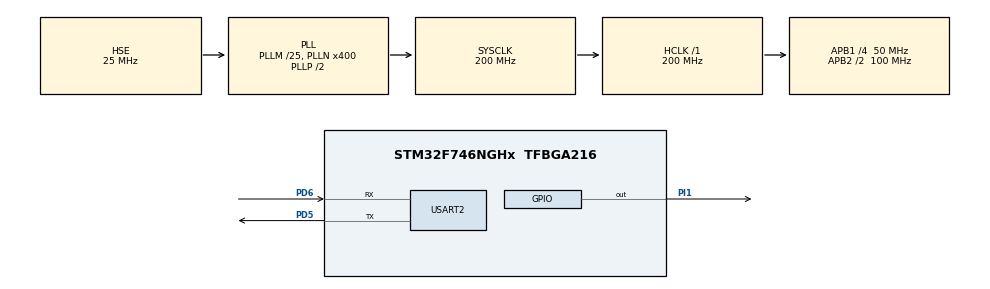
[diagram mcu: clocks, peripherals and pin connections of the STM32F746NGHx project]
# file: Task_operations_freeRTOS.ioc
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FREERTOS.INCLUDE_vTaskDelayUntil=1
FREERTOS.Tasks01=defaultTask,0,128,StartDefaultTask,Default,NULL,Dynamic,NULL,NULL;Task2,0,128,task2_init,Default,NULL,Dynamic,NULL,NULL
Mcu.Family=STM32F7
Mcu.Name=STM32F746NGHx
Mcu.Package=TFBGA216
NVIC.PriorityGroup=NVIC_PRIORITYGROUP_4
NVIC.TIM1_UP_TIM10_IRQn=true\:15\:0\:false\:false\:true\:false\:false\:true
NVIC.TimeBase=TIM1_UP_TIM10_IRQn
NVIC.TimeBaseIP=TIM1
PA13.Mode=Serial_Wire
PA13.Signal=SYS_JTMS-SWDIO
PA14.Mode=Serial_Wire
PA14.Signal=SYS_JTCK-SWCLK
PD5.Mode=Asynchronous
PD5.Signal=USART2_TX
PD6.Mode=Asynchronous
PD6.Signal=USART2_RX
PH0/OSC_IN.Mode=HSE-External-Oscillator
PH0/OSC_IN.Signal=RCC_OSC_IN
PH1/OSC_OUT.Mode=HSE-External-Oscillator
PH1/OSC_OUT.Signal=RCC_OSC_OUT
PI1.Signal=GPIO_Output
ProjectManager.HeapSize=0x200
ProjectManager.StackSize=0x400
ProjectManager.TargetToolchain=STM32CubeIDE
RCC.AHBFreq_Value=200000000
RCC.APB1CLKDivider=RCC_HCLK_DIV4
RCC.APB1Freq_Value=50000000
RCC.APB1TimFreq_Value=100000000
RCC.APB2CLKDivider=RCC_HCLK_DIV2
RCC.APB2Freq_Value=100000000
RCC.APB2TimFreq_Value=200000000
RCC.CortexFreq_Value=200000000
RCC.HCLKFreq_Value=200000000
RCC.HSE_VALUE=25000000
RCC.HSI_VALUE=16000000
RCC.LSE_VALUE=32768
RCC.PLL48CLockSelection=RCC_CLK48SOURCE_PLLSAIP
RCC.PLLI2SN=100
RCC.PLLM=25
RCC.PLLN=400
RCC.PLLQ=9
RCC.PLLSAIN=384
RCC.PLLSAIP=RCC_PLLSAIP_DIV8
RCC.PLLSAIR=5
RCC.PLLSAIRDiv=RCC_PLLSAIDIVR_8
RCC.PLLSourceVirtual=RCC_PLLSOURCE_HSE
RCC.SDMMCClockSelection=RCC_SDMMC1CLKSOURCE_CLK48
RCC.SYSCLKFreq_VALUE=200000000
RCC.SYSCLKSource=RCC_SYSCLKSOURCE_PLLCLK
RCC.USBFreq_Value=48000000
RCC.VCOOutputFreq_Value=400000000
USART2.VirtualMode-Asynchronous=VM_ASYNC
VP_FREERTOS_VS_CMSIS_V1.Mode=CMSIS_V1
VP_SYS_VS_tim1.Mode=TIM1
board=STM32F746G-DISCO

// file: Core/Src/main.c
/* USER CODE BEGIN Header */
/**
  ******************************************************************************
  * @file           : main.c
  * @brief          : Main program body
  ******************************************************************************
  * @attention
  *
  * Copyright (c) 2022 STMicroelectronics.
  * All rights reserved.
  *
  * This software is licensed under terms that can be found in the LICENSE file
  * in the root directory of this software component.
  * If no LICENSE file comes with this software, it is provided AS-IS.
  *
  ******************************************************************************
  */
/* USER CODE END Header */
#include "main.h"
#include "cmsis_os.h"
/* USER CODE BEGIN Includes */
#include <stdio.h>

/* USER CODE END Includes */

UART_HandleTypeDef huart2;

osThreadId defaultTaskHandle;
osThreadId Task2Handle;

void SystemClock_Config(void);
static void MX_GPIO_Init(void);
static void MX_USART2_UART_Init(void);
void StartDefaultTask(void const * argument);
void task2_init(void const * argument);

/* USER CODE BEGIN 0 */
int _write(int file, char *ptr, int len){
	HAL_UART_Transmit(&huart2, (uint8_t *)ptr, len, HAL_MAX_DELAY);
	return len;
}

uint8_t indx = 0;

/* USER CODE END 0 */

int main(void)
{

  /* MCU Configuration--------------------------------------------------------*/

  /* Reset of all peripherals, Initializes the Flash interface and the Systick. */
  HAL_Init();

  /* Configure the system clock */
  SystemClock_Config();

  /* Initialize all configured peripherals */
  MX_GPIO_Init();
  MX_USART2_UART_Init();
  /* USER CODE BEGIN 2 */
  printf ("starting....\n");

  /* USER CODE END 2 */

  /* Create the thread(s) */
  /* definition and creation of defaultTask */
  osThreadDef(defaultTask, StartDefaultTask, osPriorityNormal, 0, 128);
  defaultTaskHandle = osThreadCreate(osThread(defaultTask), NULL);

  /* definition and creation of Task2 */
  osThreadDef(Task2, task2_init, osPriorityNormal, 0, 128);
  Task2Handle = osThreadCreate(osThread(Task2), NULL);

  /* Start scheduler */
  osKernelStart();

  /* We should never get here as control is now taken by the scheduler */
  /* Infinite loop */
  while (1)
  {

  }
}

void SystemClock_Config(void)
{
  RCC_OscInitTypeDef RCC_OscInitStruct = {0};
  RCC_ClkInitTypeDef RCC_ClkInitStruct = {0};

  /** Configure the main internal regulator output voltage
  */
  __HAL_RCC_PWR_CLK_ENABLE();
  __HAL_PWR_VOLTAGESCALING_CONFIG(PWR_REGULATOR_VOLTAGE_SCALE1);
  /** Initializes the RCC Oscillators according to the specified parameters
  * in the RCC_OscInitTypeDef structure.
  */
  RCC_OscInitStruct.OscillatorType = RCC_OSCILLATORTYPE_HSE;
  RCC_OscInitStruct.HSEState = RCC_HSE_ON;
  RCC_OscInitStruct.PLL.PLLState = RCC_PLL_ON;
  RCC_OscInitStruct.PLL.PLLSource = RCC_PLLSOURCE_HSE;
  RCC_OscInitStruct.PLL.PLLM = 25;
  RCC_OscInitStruct.PLL.PLLN = 400;
  RCC_OscInitStruct.PLL.PLLP = RCC_PLLP_DIV2;
  RCC_OscInitStruct.PLL.PLLQ = 9;
  if (HAL_RCC_OscConfig(&RCC_OscInitStruct) != HAL_OK)
  {
    Error_Handler();
  }
  /** Activate the Over-Drive mode
  */
  if (HAL_PWREx_EnableOverDrive() != HAL_OK)
  {
    Error_Handler();
  }
  /** Initializes the CPU, AHB and APB buses clocks
  */
  RCC_ClkInitStruct.ClockType = RCC_CLOCKTYPE_HCLK|RCC_CLOCKTYPE_SYSCLK
                              |RCC_CLOCKTYPE_PCLK1|RCC_CLOCKTYPE_PCLK2;
  RCC_ClkInitStruct.SYSCLKSource = RCC_SYSCLKSOURCE_PLLCLK;
  RCC_ClkInitStruct.AHBCLKDivider = RCC_SYSCLK_DIV1;
  RCC_ClkInitStruct.APB1CLKDivider = RCC_HCLK_DIV4;
  RCC_ClkInitStruct.APB2CLKDivider = RCC_HCLK_DIV2;

  if (HAL_RCC_ClockConfig(&RCC_ClkInitStruct, FLASH_LATENCY_6) != HAL_OK)
  {
    Error_Handler();
  }
}

static void MX_USART2_UART_Init(void)
{

  huart2.Instance = USART2;
  huart2.Init.BaudRate = 115200;
  huart2.Init.WordLength = UART_WORDLENGTH_8B;
  huart2.Init.StopBits = UART_STOPBITS_1;
  huart2.Init.Parity = UART_PARITY_NONE;
  huart2.Init.Mode = UART_MODE_TX_RX;
  huart2.Init.HwFlowCtl = UART_HWCONTROL_NONE;
  huart2.Init.OverSampling = UART_OVERSAMPLING_16;
  huart2.Init.OneBitSampling = UART_ONE_BIT_SAMPLE_DISABLE;
  huart2.AdvancedInit.AdvFeatureInit = UART_ADVFEATURE_NO_INIT;
  if (HAL_UART_Init(&huart2) != HAL_OK)
  {
    Error_Handler();
  }

}

static void MX_GPIO_Init(void)
{
  GPIO_InitTypeDef GPIO_InitStruct = {0};

  /* GPIO Ports Clock Enable */
  __HAL_RCC_GPIOA_CLK_ENABLE();
  __HAL_RCC_GPIOD_CLK_ENABLE();
  __HAL_RCC_GPIOI_CLK_ENABLE();
  __HAL_RCC_GPIOH_CLK_ENABLE();

  /*Configure GPIO pin Output Level */
  HAL_GPIO_WritePin(GPIOI, GPIO_PIN_1, GPIO_PIN_RESET);

  /*Configure GPIO pin : PI1 */
  GPIO_InitStruct.Pin = GPIO_PIN_1;
  GPIO_InitStruct.Mode = GPIO_MODE_OUTPUT_PP;
  GPIO_InitStruct.Pull = GPIO_NOPULL;
  GPIO_InitStruct.Speed = GPIO_SPEED_FREQ_LOW;
  HAL_GPIO_Init(GPIOI, &GPIO_InitStruct);

}

void StartDefaultTask(void const * argument)
{
  /* USER CODE BEGIN 5 */
  /* Infinite loop */
  for(;;)
  {
	  printf ("DefaultTask\n");
	      osDelay(1000);
  }
  /* USER CODE END 5 */
}

void task2_init(void const * argument)
{
  /* USER CODE BEGIN task2_init */
  /* Infinite loop */
  while(1)
  {
	  HAL_GPIO_TogglePin(GPIOI, GPIO_PIN_1);
	  printf ("Task2 = %d\n", indx++);
	  osDelay(2000);
	  if (indx == 3)
	  		{
	  			uint32_t PreviousWakeTime = osKernelSysTick();
	  			osDelayUntil(&PreviousWakeTime, 3000);  // 3 sec inactive
	  		}
  }
  /* USER CODE END task2_init */
}

void HAL_TIM_PeriodElapsedCallback(TIM_HandleTypeDef *htim)
{
  if (htim->Instance == TIM1) {
    HAL_IncTick();
  }
}

void Error_Handler(void)
{
  __disable_irq();
  while (1)
  {
  }
}
